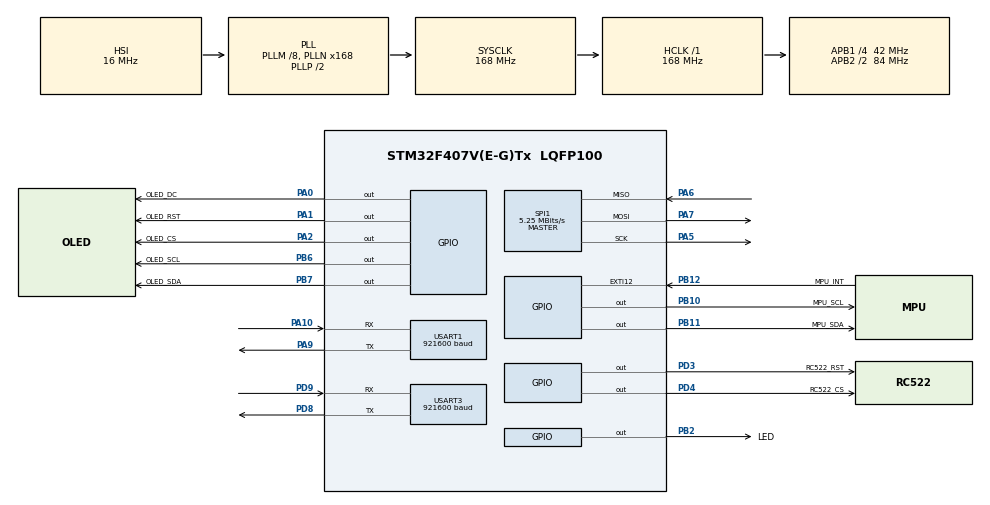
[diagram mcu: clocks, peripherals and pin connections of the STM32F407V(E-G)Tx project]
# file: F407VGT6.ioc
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Dma.Request0=USART1_RX
Dma.Request1=USART1_TX
Dma.Request2=USART3_RX
Dma.Request3=USART3_TX
Dma.USART1_RX.0.Direction=DMA_PERIPH_TO_MEMORY
Dma.USART1_RX.0.FIFOMode=DMA_FIFOMODE_ENABLE
Dma.USART1_RX.0.FIFOThreshold=DMA_FIFO_THRESHOLD_FULL
Dma.USART1_RX.0.Instance=DMA2_Stream2
Dma.USART1_RX.0.MemBurst=DMA_MBURST_SINGLE
Dma.USART1_RX.0.MemDataAlignment=DMA_MDATAALIGN_BYTE
Dma.USART1_RX.0.MemInc=DMA_MINC_ENABLE
Dma.USART1_RX.0.Mode=DMA_NORMAL
Dma.USART1_RX.0.PeriphBurst=DMA_PBURST_SINGLE
Dma.USART1_RX.0.PeriphDataAlignment=DMA_PDATAALIGN_BYTE
Dma.USART1_RX.0.PeriphInc=DMA_PINC_DISABLE
Dma.USART1_RX.0.Priority=DMA_PRIORITY_LOW
Dma.USART1_TX.1.Direction=DMA_MEMORY_TO_PERIPH
Dma.USART1_TX.1.FIFOMode=DMA_FIFOMODE_ENABLE
Dma.USART1_TX.1.FIFOThreshold=DMA_FIFO_THRESHOLD_FULL
Dma.USART1_TX.1.Instance=DMA2_Stream7
Dma.USART1_TX.1.MemBurst=DMA_MBURST_SINGLE
Dma.USART1_TX.1.MemDataAlignment=DMA_MDATAALIGN_BYTE
Dma.USART1_TX.1.MemInc=DMA_MINC_ENABLE
Dma.USART1_TX.1.Mode=DMA_NORMAL
Dma.USART1_TX.1.PeriphBurst=DMA_PBURST_SINGLE
Dma.USART1_TX.1.PeriphDataAlignment=DMA_PDATAALIGN_BYTE
Dma.USART1_TX.1.PeriphInc=DMA_PINC_DISABLE
Dma.USART1_TX.1.Priority=DMA_PRIORITY_LOW
Dma.USART3_RX.2.Direction=DMA_PERIPH_TO_MEMORY
Dma.USART3_RX.2.FIFOMode=DMA_FIFOMODE_ENABLE
Dma.USART3_RX.2.FIFOThreshold=DMA_FIFO_THRESHOLD_FULL
Dma.USART3_RX.2.Instance=DMA1_Stream1
Dma.USART3_RX.2.MemBurst=DMA_MBURST_SINGLE
Dma.USART3_RX.2.MemDataAlignment=DMA_MDATAALIGN_BYTE
Dma.USART3_RX.2.MemInc=DMA_MINC_ENABLE
Dma.USART3_RX.2.Mode=DMA_NORMAL
Dma.USART3_RX.2.PeriphBurst=DMA_PBURST_SINGLE
Dma.USART3_RX.2.PeriphDataAlignment=DMA_PDATAALIGN_BYTE
Dma.USART3_RX.2.PeriphInc=DMA_PINC_DISABLE
Dma.USART3_RX.2.Priority=DMA_PRIORITY_LOW
Dma.USART3_TX.3.Direction=DMA_MEMORY_TO_PERIPH
Dma.USART3_TX.3.FIFOMode=DMA_FIFOMODE_ENABLE
Dma.USART3_TX.3.FIFOThreshold=DMA_FIFO_THRESHOLD_FULL
Dma.USART3_TX.3.Instance=DMA1_Stream3
Dma.USART3_TX.3.MemBurst=DMA_MBURST_SINGLE
Dma.USART3_TX.3.MemDataAlignment=DMA_MDATAALIGN_BYTE
Dma.USART3_TX.3.MemInc=DMA_MINC_ENABLE
Dma.USART3_TX.3.Mode=DMA_NORMAL
Dma.USART3_TX.3.PeriphBurst=DMA_PBURST_SINGLE
Dma.USART3_TX.3.PeriphDataAlignment=DMA_PDATAALIGN_BYTE
Dma.USART3_TX.3.PeriphInc=DMA_PINC_DISABLE
Dma.USART3_TX.3.Priority=DMA_PRIORITY_LOW
Mcu.Family=STM32F4
Mcu.Name=STM32F407V(E-G)Tx
Mcu.Package=LQFP100
NVIC.DMA1_Stream1_IRQn=true\:0\:0\:false\:false\:true\:false\:true\:true
NVIC.DMA1_Stream3_IRQn=true\:0\:0\:false\:false\:true\:false\:true\:true
NVIC.DMA2_Stream2_IRQn=true\:0\:0\:false\:false\:true\:false\:true\:true
NVIC.DMA2_Stream7_IRQn=true\:0\:0\:false\:false\:true\:false\:true\:true
NVIC.EXTI15_10_IRQn=true\:0\:0\:false\:false\:true\:true\:true\:true
NVIC.PriorityGroup=NVIC_PRIORITYGROUP_4
NVIC.RTC_WKUP_IRQn=true\:0\:0\:false\:false\:true\:true\:true\:true
NVIC.SPI1_IRQn=true\:0\:0\:false\:false\:true\:true\:true\:true
NVIC.USART1_IRQn=true\:0\:0\:false\:false\:true\:true\:true\:true
NVIC.USART3_IRQn=true\:0\:0\:false\:false\:true\:true\:true\:true
PA0-WKUP.GPIO_Label=OLED_DC
PA0-WKUP.GPIO_Speed=GPIO_SPEED_FREQ_MEDIUM
PA0-WKUP.PinState=GPIO_PIN_SET
PA0-WKUP.Signal=GPIO_Output
PA1.GPIO_Label=OLED_RST
PA1.GPIO_Speed=GPIO_SPEED_FREQ_LOW
PA1.PinState=GPIO_PIN_SET
PA1.Signal=GPIO_Output
PA10.Mode=Asynchronous
PA10.Signal=USART1_RX
PA2.GPIO_Label=OLED_CS
PA2.GPIO_Speed=GPIO_SPEED_FREQ_MEDIUM
PA2.PinState=GPIO_PIN_SET
PA2.Signal=GPIO_Output
PA5.Mode=Full_Duplex_Master
PA5.Signal=SPI1_SCK
PA6.Mode=Full_Duplex_Master
PA6.Signal=SPI1_MISO
PA7.Mode=Full_Duplex_Master
PA7.Signal=SPI1_MOSI
PA9.Mode=Asynchronous
PA9.Signal=USART1_TX
PB10.GPIO_Label=MPU_SCL
PB10.GPIO_ModeDefaultOutputPP=GPIO_MODE_OUTPUT_OD
PB10.GPIO_PuPd=GPIO_NOPULL
PB10.GPIO_Speed=GPIO_SPEED_FREQ_VERY_HIGH
PB10.PinState=GPIO_PIN_SET
PB10.Signal=GPIO_Output
PB11.GPIO_Label=MPU_SDA
PB11.GPIO_ModeDefaultOutputPP=GPIO_MODE_OUTPUT_OD
PB11.GPIO_PuPd=GPIO_NOPULL
PB11.GPIO_Speed=GPIO_SPEED_FREQ_VERY_HIGH
PB11.PinState=GPIO_PIN_SET
PB11.Signal=GPIO_Output
PB12.GPIO_Label=MPU_INT
PB12.GPIO_ModeDefaultEXTI=GPIO_MODE_IT_RISING
PB12.GPIO_PuPd=GPIO_NOPULL
PB12.Signal=GPXTI12
PB2.GPIO_Label=LED
PB2.Signal=GPIO_Output
PB6.GPIO_Label=OLED_SCL
PB6.GPIO_ModeDefaultOutputPP=GPIO_MODE_OUTPUT_OD
PB6.GPIO_PuPd=GPIO_NOPULL
PB6.GPIO_Speed=GPIO_SPEED_FREQ_VERY_HIGH
PB6.PinState=GPIO_PIN_SET
PB6.Signal=GPIO_Output
PB7.GPIO_Label=OLED_SDA
PB7.GPIO_ModeDefaultOutputPP=GPIO_MODE_OUTPUT_OD
PB7.GPIO_PuPd=GPIO_NOPULL
PB7.GPIO_Speed=GPIO_SPEED_FREQ_VERY_HIGH
PB7.PinState=GPIO_PIN_SET
PB7.Signal=GPIO_Output
PC14-OSC32_IN.Mode=LSE-External-Oscillator
PC14-OSC32_IN.Signal=RCC_OSC32_IN
PC15-OSC32_OUT.Mode=LSE-External-Oscillator
PC15-OSC32_OUT.Signal=RCC_OSC32_OUT
PD3.GPIO_Label=RC522_RST
PD3.PinState=GPIO_PIN_SET
PD3.Signal=GPIO_Output
PD4.GPIO_Label=RC522_CS
PD4.GPIO_Speed=GPIO_SPEED_FREQ_MEDIUM
PD4.PinState=GPIO_PIN_SET
PD4.Signal=GPIO_Output
PD8.Mode=Asynchronous
PD8.Signal=USART3_TX
PD9.Mode=Asynchronous
PD9.Signal=USART3_RX
PH0-OSC_IN.Mode=HSE-External-Oscillator
PH0-OSC_IN.Signal=RCC_OSC_IN
PH1-OSC_OUT.Mode=HSE-External-Oscillator
PH1-OSC_OUT.Signal=RCC_OSC_OUT
ProjectManager.HeapSize=0x200
ProjectManager.StackSize=0x400
ProjectManager.TargetToolchain=CMake
RCC.48MHZClocksFreq_Value=84000000
RCC.AHBFreq_Value=168000000
RCC.APB1CLKDivider=RCC_HCLK_DIV4
RCC.APB1Freq_Value=42000000
RCC.APB1TimFreq_Value=84000000
RCC.APB2CLKDivider=RCC_HCLK_DIV2
RCC.APB2Freq_Value=84000000
RCC.APB2TimFreq_Value=168000000
RCC.CortexFreq_Value=168000000
RCC.HCLKFreq_Value=168000000
RCC.HSE_VALUE=25000000
RCC.HSI_VALUE=16000000
RCC.PLLM=8
RCC.PLLN=168
RCC.RCC_RTC_Clock_Source=RCC_RTCCLKSOURCE_LSE
RCC.RCC_RTC_Clock_SourceVirtual=RCC_RTCCLKSOURCE_LSE
RCC.SYSCLKFreq_VALUE=168000000
RCC.SYSCLKSource=RCC_SYSCLKSOURCE_PLLCLK
RCC.VCOOutputFreq_Value=336000000
RTC.Date=12
RTC.Format=RTC_FORMAT_BIN
RTC.Hours=22
RTC.Minutes=22
RTC.Month=RTC_MONTH_JULY
RTC.StoreOperation=RTC_STOREOPERATION_SET
RTC.WakeUpClock=RTC_WAKEUPCLOCK_CK_SPRE_16BITS
RTC.WeekDay=RTC_WEEKDAY_SUNDAY
RTC.Year=26
SPI1.BaudRatePrescaler=SPI_BAUDRATEPRESCALER_16
SPI1.CalculateBaudRate=5.25 MBits/s
SPI1.Direction=SPI_DIRECTION_2LINES
SPI1.Mode=SPI_MODE_MASTER
SPI1.VirtualType=VM_MASTER
STMicroelectronics.X-CUBE-ALGOBUILD.1.5.0.LibraryCcDSPOoLibraryJjDSPOoLibrary=true
TIM7.Prescaler=84-1
USART1.BaudRate=921600
USART1.VirtualMode=VM_ASYNC
USART3.BaudRate=921600
USART3.VirtualMode=VM_ASYNC
VP_RTC_VS_RTC_Activate.Mode=RTC_Enabled
VP_RTC_VS_RTC_Calendar.Mode=RTC_Calendar
VP_RTC_VS_RTC_WakeUp_intern.Mode=WakeUp
VP_STMicroelectronics.X-CUBE-ALGOBUILD_VS_DSPOoLibraryJjLibrary_1.5.0_1.5.0.Mode=DSPOoLibraryJjLibrary
VP_TIM7_VS_ClockSourceINT.Mode=Enable_Timer
board=custom

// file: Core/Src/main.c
/* USER CODE BEGIN Header */
/**
  ******************************************************************************
  * @file           : main.c
  * @brief          : Main program body
  ******************************************************************************
  * @attention
  *
  * Copyright (c) 2026 STMicroelectronics.
  * All rights reserved.
  *
  * This software is licensed under terms that can be found in the LICENSE file
  * in the root directory of this software component.
  * If no LICENSE file comes with this software, it is provided AS-IS.
  *
  ******************************************************************************
  */
/* USER CODE END Header */
#include "main.h"
#include "dma.h"
#include "rtc.h"
#include "spi.h"
#include "tim.h"
#include "usart.h"
#include "gpio.h"

/* USER CODE BEGIN Includes */
#include "bsp_delay.h"
#include "app_usart.h"
//#include "tim.h"
#include "app_oled.h"
#include "app_rtc.h"
//#include "rc522_config.h"
#include "app_mpu.h"
//#include "usmart_config.h"
/* USER CODE END Includes */

void SystemClock_Config(void);

int main(void)
{

  /* MCU Configuration--------------------------------------------------------*/

  /* Reset of all peripherals, Initializes the Flash interface and the Systick. */
  HAL_Init();

  /* Configure the system clock */
  SystemClock_Config();

  /* Initialize all configured peripherals */
  MX_GPIO_Init();
  MX_DMA_Init();
  MX_USART1_UART_Init();
  MX_RTC_Init();
  MX_TIM7_Init();
  MX_SPI1_Init();
  MX_USART3_UART_Init();
  /* USER CODE BEGIN 2 */
  DWT_Init();
  usart_init();
  oled_init();
  rtc_display();
  //RC522_Init();
  mpu_init();
  /* USER CODE END 2 */

  /* Infinite loop */
  /* USER CODE BEGIN WHILE */
  while (1)
  {
    rtc_display();
    mpu_task();
    task_list();
    //Find_Card_Task();
    //task_list();
    //Usart_Print(&TX1_handle, "VERSION:%x\r\n",RC522_RD_Reg(VersionReg));
    /* USER CODE END WHILE */

  }
}

void SystemClock_Config(void)
{
  RCC_OscInitTypeDef RCC_OscInitStruct = {0};
  RCC_ClkInitTypeDef RCC_ClkInitStruct = {0};

  /** Configure the main internal regulator output voltage
  */
  __HAL_RCC_PWR_CLK_ENABLE();
  __HAL_PWR_VOLTAGESCALING_CONFIG(PWR_REGULATOR_VOLTAGE_SCALE1);

  /** Initializes the RCC Oscillators according to the specified parameters
  * in the RCC_OscInitTypeDef structure.
  */
  RCC_OscInitStruct.OscillatorType = RCC_OSCILLATORTYPE_HSI|RCC_OSCILLATORTYPE_LSE;
  RCC_OscInitStruct.LSEState = RCC_LSE_ON;
  RCC_OscInitStruct.HSIState = RCC_HSI_ON;
  RCC_OscInitStruct.HSICalibrationValue = RCC_HSICALIBRATION_DEFAULT;
  RCC_OscInitStruct.PLL.PLLState = RCC_PLL_ON;
  RCC_OscInitStruct.PLL.PLLSource = RCC_PLLSOURCE_HSI;
  RCC_OscInitStruct.PLL.PLLM = 8;
  RCC_OscInitStruct.PLL.PLLN = 168;
  RCC_OscInitStruct.PLL.PLLP = RCC_PLLP_DIV2;
  RCC_OscInitStruct.PLL.PLLQ = 4;
  if (HAL_RCC_OscConfig(&RCC_OscInitStruct) != HAL_OK)
  {
    Error_Handler();
  }

  /** Initializes the CPU, AHB and APB buses clocks
  */
  RCC_ClkInitStruct.ClockType = RCC_CLOCKTYPE_HCLK|RCC_CLOCKTYPE_SYSCLK
                              |RCC_CLOCKTYPE_PCLK1|RCC_CLOCKTYPE_PCLK2;
  RCC_ClkInitStruct.SYSCLKSource = RCC_SYSCLKSOURCE_PLLCLK;
  RCC_ClkInitStruct.AHBCLKDivider = RCC_SYSCLK_DIV1;
  RCC_ClkInitStruct.APB1CLKDivider = RCC_HCLK_DIV4;
  RCC_ClkInitStruct.APB2CLKDivider = RCC_HCLK_DIV2;

  if (HAL_RCC_ClockConfig(&RCC_ClkInitStruct, FLASH_LATENCY_5) != HAL_OK)
  {
    Error_Handler();
  }
}

void Error_Handler(void)
{
  __disable_irq();
  while (1)
  {
  }
}
